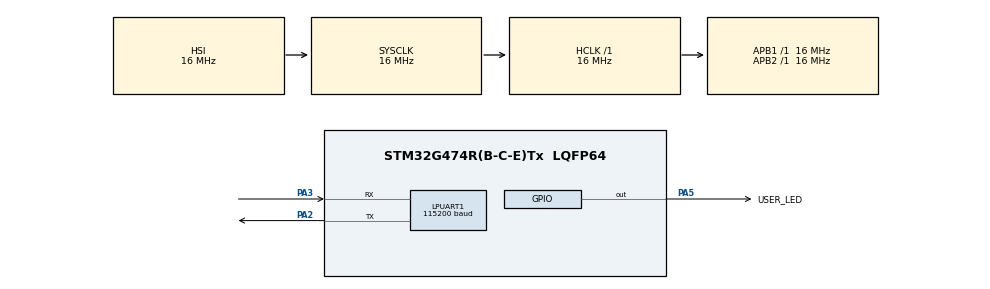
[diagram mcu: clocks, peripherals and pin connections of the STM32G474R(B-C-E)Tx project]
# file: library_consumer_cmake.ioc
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LPUART1.BaudRate=115200
Mcu.Family=STM32G4
Mcu.Name=STM32G474R(B-C-E)Tx
Mcu.Package=LQFP64
NVIC.PriorityGroup=NVIC_PRIORITYGROUP_4
PA2.Mode=Asynchronous
PA2.Signal=LPUART1_TX
PA3.Mode=Asynchronous
PA3.Signal=LPUART1_RX
PA5.GPIO_Label=USER_LED
PA5.Signal=GPIO_Output
PF0-OSC_IN.Mode=HSE-External-Oscillator
PF0-OSC_IN.Signal=RCC_OSC_IN
PF1-OSC_OUT.Mode=HSE-External-Oscillator
PF1-OSC_OUT.Signal=RCC_OSC_OUT
ProjectManager.HeapSize=0x200
ProjectManager.StackSize=0x400
ProjectManager.TargetToolchain=CMake
RCC.ADC12Freq_Value=16000000
RCC.ADC345Freq_Value=16000000
RCC.AHBFreq_Value=16000000
RCC.APB1Freq_Value=16000000
RCC.APB1TimFreq_Value=16000000
RCC.APB2Freq_Value=16000000
RCC.APB2TimFreq_Value=16000000
RCC.CortexFreq_Value=16000000
RCC.EXTERNAL_CLOCK_VALUE=12288000
RCC.HCLKFreq_Value=16000000
RCC.HSE_VALUE=24000000
RCC.HSI48_VALUE=48000000
RCC.HSI_VALUE=16000000
RCC.LSE_VALUE=32768
RCC.PLLM=RCC_PLLM_DIV2
RCC.SYSCLKFreq_VALUE=16000000
RCC.USBFreq_Value=32000000
RCC.VCOOutputFreq_Value=64000000
VP_SYS_VS_DBSignals.Mode=DisableDeadBatterySignals
board=custom

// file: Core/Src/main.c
/* USER CODE BEGIN Header */
/**
  ******************************************************************************
  * @file           : main.c
  * @brief          : Main program body
  ******************************************************************************
  * @attention
  *
  * Copyright (c) 2026 STMicroelectronics.
  * All rights reserved.
  *
  * This software is licensed under terms that can be found in the LICENSE file
  * in the root directory of this software component.
  * If no LICENSE file comes with this software, it is provided AS-IS.
  *
  ******************************************************************************
  */
/* USER CODE END Header */
#include "main.h"

/* USER CODE BEGIN Includes */
#include "stm32g4xx_hal.h"
#include "stm32g4xx_hal_gpio.h"
#include "uart_handler.h"
#include "command_parser.h"
#include <stdint.h>
/* USER CODE END Includes */

UART_HandleTypeDef hlpuart1;

void SystemClock_Config(void);
static void MX_GPIO_Init(void);
static void MX_LPUART1_UART_Init(void);

int main(void)
{

  /* MCU Configuration--------------------------------------------------------*/

  /* Reset of all peripherals, Initializes the Flash interface and the Systick. */
  HAL_Init();

  /* Configure the system clock */
  SystemClock_Config();

  /* Initialize all configured peripherals */
  MX_GPIO_Init();
  MX_LPUART1_UART_Init();
  /* USER CODE BEGIN 2 */
  set_uart(&hlpuart1);
  int blinking = 0;
  int rate = 1000;
  int last_blink = HAL_GetTick();
  HAL_GPIO_WritePin(USER_LED_GPIO_Port, USER_LED_Pin, GPIO_PIN_RESET);
  /* USER CODE END 2 */

  /* Infinite loop */
  /* USER CODE BEGIN WHILE */
  while (1)
  {
    fill_buffer();
    int good_read = 1;
    while (good_read){
      char* slice;
      int read_bytes = read_buffer_slice(5, &slice);
      if (read_bytes<=0){
        good_read = 0;
        clear_buffer_slice();
        continue;
      }
      if (read_bytes == 5){
        command_t command;
        parse(slice, 5, &command);
        switch (command.type){
          case LIGHT_STATE:
            blinking = command.data;
            break;

          case LIGHT_SPEED:
            rate = command.data;
            break;

          default:
            break;
        }
      }
      clear_buffer_slice();
    }
    int current_tick = HAL_GetTick();
    if (blinking && current_tick-last_blink >= rate){
      HAL_GPIO_TogglePin(USER_LED_GPIO_Port, USER_LED_Pin);
      last_blink = current_tick;
    }
    if (!blinking){
      HAL_GPIO_WritePin(USER_LED_GPIO_Port, USER_LED_Pin, GPIO_PIN_RESET);
    }
    /* USER CODE END WHILE */

  }
}

void SystemClock_Config(void)
{
  RCC_OscInitTypeDef RCC_OscInitStruct = {0};
  RCC_ClkInitTypeDef RCC_ClkInitStruct = {0};

  /** Configure the main internal regulator output voltage
  */
  HAL_PWREx_ControlVoltageScaling(PWR_REGULATOR_VOLTAGE_SCALE1);

  /** Initializes the RCC Oscillators according to the specified parameters
  * in the RCC_OscInitTypeDef structure.
  */
  RCC_OscInitStruct.OscillatorType = RCC_OSCILLATORTYPE_HSI;
  RCC_OscInitStruct.HSIState = RCC_HSI_ON;
  RCC_OscInitStruct.HSICalibrationValue = RCC_HSICALIBRATION_DEFAULT;
  RCC_OscInitStruct.PLL.PLLState = RCC_PLL_NONE;
  if (HAL_RCC_OscConfig(&RCC_OscInitStruct) != HAL_OK)
  {
    Error_Handler();
  }

  /** Initializes the CPU, AHB and APB buses clocks
  */
  RCC_ClkInitStruct.ClockType = RCC_CLOCKTYPE_HCLK|RCC_CLOCKTYPE_SYSCLK
                              |RCC_CLOCKTYPE_PCLK1|RCC_CLOCKTYPE_PCLK2;
  RCC_ClkInitStruct.SYSCLKSource = RCC_SYSCLKSOURCE_HSI;
  RCC_ClkInitStruct.AHBCLKDivider = RCC_SYSCLK_DIV1;
  RCC_ClkInitStruct.APB1CLKDivider = RCC_HCLK_DIV1;
  RCC_ClkInitStruct.APB2CLKDivider = RCC_HCLK_DIV1;

  if (HAL_RCC_ClockConfig(&RCC_ClkInitStruct, FLASH_LATENCY_0) != HAL_OK)
  {
    Error_Handler();
  }
}

static void MX_LPUART1_UART_Init(void)
{

  hlpuart1.Instance = LPUART1;
  hlpuart1.Init.BaudRate = 115200;
  hlpuart1.Init.WordLength = UART_WORDLENGTH_8B;
  hlpuart1.Init.StopBits = UART_STOPBITS_1;
  hlpuart1.Init.Parity = UART_PARITY_NONE;
  hlpuart1.Init.Mode = UART_MODE_TX_RX;
  hlpuart1.Init.HwFlowCtl = UART_HWCONTROL_NONE;
  hlpuart1.Init.OneBitSampling = UART_ONE_BIT_SAMPLE_DISABLE;
  hlpuart1.Init.ClockPrescaler = UART_PRESCALER_DIV1;
  hlpuart1.AdvancedInit.AdvFeatureInit = UART_ADVFEATURE_NO_INIT;
  if (HAL_UART_Init(&hlpuart1) != HAL_OK)
  {
    Error_Handler();
  }
  if (HAL_UARTEx_SetTxFifoThreshold(&hlpuart1, UART_TXFIFO_THRESHOLD_1_8) != HAL_OK)
  {
    Error_Handler();
  }
  if (HAL_UARTEx_SetRxFifoThreshold(&hlpuart1, UART_RXFIFO_THRESHOLD_1_8) != HAL_OK)
  {
    Error_Handler();
  }
  if (HAL_UARTEx_DisableFifoMode(&hlpuart1) != HAL_OK)
  {
    Error_Handler();
  }

}

static void MX_GPIO_Init(void)
{
  GPIO_InitTypeDef GPIO_InitStruct = {0};

  /* GPIO Ports Clock Enable */
  __HAL_RCC_GPIOF_CLK_ENABLE();
  __HAL_RCC_GPIOA_CLK_ENABLE();

  /*Configure GPIO pin Output Level */
  HAL_GPIO_WritePin(USER_LED_GPIO_Port, USER_LED_Pin, GPIO_PIN_RESET);

  /*Configure GPIO pin : USER_LED_Pin */
  GPIO_InitStruct.Pin = USER_LED_Pin;
  GPIO_InitStruct.Mode = GPIO_MODE_OUTPUT_PP;
  GPIO_InitStruct.Pull = GPIO_NOPULL;
  GPIO_InitStruct.Speed = GPIO_SPEED_FREQ_LOW;
  HAL_GPIO_Init(USER_LED_GPIO_Port, &GPIO_InitStruct);

}

void Error_Handler(void)
{
  __disable_irq();
  while (1)
  {
  }
}
